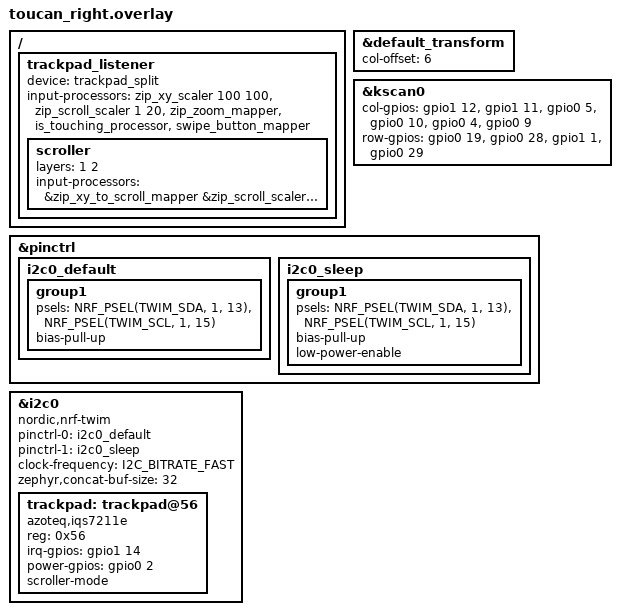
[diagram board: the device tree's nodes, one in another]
#include "toucan.dtsi"
#include <dt-bindings/zmk/input_transform.h>
#include <dt-bindings/input/input-event-codes.h>
#include <input/processors.dtsi>

&default_transform {
    col-offset = <6>;
};

&kscan0 {
    col-gpios
    = <&gpio1 12 GPIO_ACTIVE_HIGH>
    , <&gpio1 11 GPIO_ACTIVE_HIGH>
    , <&gpio0 5 GPIO_ACTIVE_HIGH>
    , <&gpio0 10 GPIO_ACTIVE_HIGH>
    , <&gpio0 4 GPIO_ACTIVE_HIGH>
    , <&gpio0 9 GPIO_ACTIVE_HIGH>
    ;

    row-gpios
    = <&gpio0 19 (GPIO_ACTIVE_HIGH | GPIO_PULL_DOWN)>
    , <&gpio0 28 (GPIO_ACTIVE_HIGH | GPIO_PULL_DOWN)>
    , <&gpio1 1 (GPIO_ACTIVE_HIGH | GPIO_PULL_DOWN)>
    , <&gpio0 29 (GPIO_ACTIVE_HIGH | GPIO_PULL_DOWN)>
    ;
};

/ {
    trackpad_listener {
        status = "okay";
        device = <&trackpad_split>;
        input-processors = <&zip_xy_scaler 100 100>, <&zip_scroll_scaler 1 20>, <&zip_zoom_mapper>, <&is_touching_processor>, <&swipe_button_mapper>;

        scroller {
            layers = <1 2>;
            input-processors = 
                &zip_xy_to_scroll_mapper
                &zip_scroll_scaler 1 20
                &zip_scroll_transform INPUT_TRANSFORM_X_INVERT
            >;
        };
    };
};

&pinctrl {
    i2c0_default: i2c0_default {
        group1 {
            psels = <NRF_PSEL(TWIM_SDA, 1, 13)>,
                    <NRF_PSEL(TWIM_SCL, 1, 15)>;
            bias-pull-up;
        };
    };

    i2c0_sleep: i2c0_sleep {
        group1 {
            psels = <NRF_PSEL(TWIM_SDA, 1, 13)>,
                    <NRF_PSEL(TWIM_SCL, 1, 15)>;
            bias-pull-up;
            low-power-enable;
        };
    };
};


&i2c0 {
    status = "okay";
    compatible = "nordic,nrf-twim";
    pinctrl-0 = <&i2c0_default>;
    pinctrl-1 = <&i2c0_sleep>;
    pinctrl-names = "default", "sleep";
    clock-frequency = <I2C_BITRATE_FAST>;
    zephyr,concat-buf-size = <32>;

    trackpad: trackpad@56 {
        status = "okay";
        compatible = "azoteq,iqs7211e";
        reg = <0x56>;
        irq-gpios = <&gpio1 14 GPIO_PULL_UP>;
        power-gpios = <&gpio0 2 GPIO_ACTIVE_HIGH>;
        scroller-mode;
        // v-invert;
    };
};
